# ATxmega128B1 device description
Architecture: AVR8_XMEGA; Family: AVR XMEGA
Registers are 8-bit, access not given, no defined reset value unless marked. A register's access mark holds for its fields unless they carry their own. Offsets are from the block's base; [hi:lo] are bit positions; lines under a group give offsets from that group; {n}, {i} and the like mark numbered series.

## ADC — Analog-to-Digital Converter
Instances: ADCA 0x0200, ADCB 0x0240
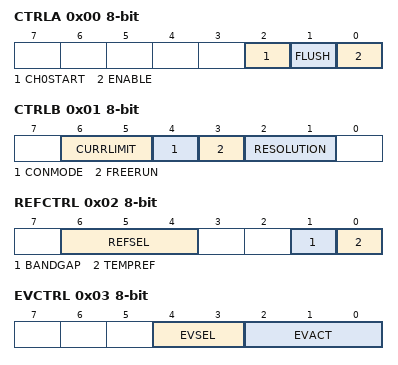
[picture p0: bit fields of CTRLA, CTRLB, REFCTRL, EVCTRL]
0x00 CTRLA — Control Register A
  [2] CH0START — Channel 0 Start Conversion
  [1] FLUSH — ADC Flush
  [0] ENABLE — Enable ADC
0x01 CTRLB — Control Register B
  [6:5] CURRLIMIT — Current limit
    0=NO (No current limit, 300ksps max sampling rate); 1=LOW (Low current limit, 250ksps max sampling rate); 2=MED (Medium current limit, 150ksps max sampling rate); 3=HIGH (High current limit, 50ksps max sampling rate)
  [4] CONMODE — Conversion Mode
  [3] FREERUN — Free Running Mode Enable
  [2:1] RESOLUTION — Result Resolution
    0=12BIT (12-bit right-adjusted result); 2=8BIT (8-bit right-adjusted result); 3=LEFT12BIT (12-bit left-adjusted result)
0x02 REFCTRL — Reference Control
  [6:4] REFSEL — Reference Selection
    0=INT1V (Internal 1V); 1=INTVCC (Internal VCC / 1.6); 2=AREFA (External reference on PORT A); 3=AREFB (External reference on PORT B); 4=INTVCC2 (Internal VCC / 2)
  [1] BANDGAP — Bandgap enable
  [0] TEMPREF — Temperature Reference Enable
0x03 EVCTRL — Event Control
  [4:3] EVSEL — Event Input Select
    {v}=Event Channel {v} (v=0..3)
  [2:0] EVACT — Event Action Select
    0=NONE (No event action); 1=CH0 (First event triggers channel 0); 6=SYNCSWEEP (The ADC is flushed and restarted for accurate timing)
0x04 PRESCALER — Clock Prescaler
  [2:0] PRESCALER — Clock Prescaler Selection
    0=DIV4 (Divide clock by 4); 1=DIV8 (Divide clock by 8); 2=DIV16 (Divide clock by 16); 3=DIV32 (Divide clock by 32); 4=DIV64 (Divide clock by 64); 5=DIV128 (Divide clock by 128); 6=DIV256 (Divide clock by 256); 7=DIV512 (Divide clock by 512)
0x06 INTFLAGS — Interrupt Flags
  [0] CH0IF — Channel 0 Interrupt Flag
0x07 TEMP — Temporary Register
0x08 SAMPCTRL — ADC Sampling Time Control Register
  [5:0] SAMPVAL — Sampling time control register
0x0C CAL 16-bit — Calibration Value
0x10 CH0RES 16-bit — Channel 0 Result
0x18 CMP 16-bit — Compare Value
0x20 CH0 group — ADC Channel 0
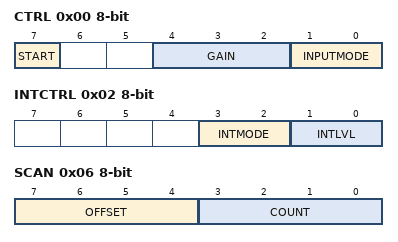
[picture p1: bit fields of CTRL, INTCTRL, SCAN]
  0x00 CTRL — Control Register
    [7] START — Channel Start Conversion
    [4:2] GAIN — Gain Factor
      0=1x gain; 1=2X (2x gain); 2=4X (4x gain); 3=8X (8x gain); 4=16X (16x gain); 5=32X (32x gain); 6=64X (64x gain); 7=DIV2 (x/2 gain)
    [1:0] INPUTMODE — Input Mode Select
      0=INTERNAL (Internal inputs, no gain (INPUTMODE = 0)); 1=SINGLEENDED (Single-ended input, no gain (INPUTMODE = 1)); 2=DIFF (Differential input, no gain (INPUTMODE = 2)); 3=DIFFWGAIN (Differential input, with gain (INPUTMODE = 3))
  0x01 MUXCTRL — MUX Control
    [6:3] MUXPOS — MUX selection on Positive ADC input
      {v}=PIN{v} (Input pin {v}) (v=0..15)
    [6:3] MUXINT — MUX selection on Internal ADC input
      0=TEMP (Temperature Reference); 1=BANDGAP (Bandgap Reference); 2=SCALEDVCC (1/10 scaled VCC)
    [2:0] MUXNEG — MUX selection on Negative ADC input
      0=PIN0 (Input pin 0 (if INPUTMODE = 2)); 1=PIN1 (Input pin 1 (if INPUTMODE = 2)); 2=PIN2 (Input pin 2 (if INPUTMODE = 2)); 3=PIN3 (Input pin 3 (if INPUTMODE = 2)); 0=PIN4 (Input pin 4 (if INPUTMODE = 3)); 1=PIN5 (Input pin 5 (if INPUTMODE = 3)); 2=PIN6 (Input pin 6 (if INPUTMODE = 3)); 3=PIN7 (Input pin 7 (if INPUTMODE = 3)); 5=GND_MODE3 (PAD Ground (if INPUTMODE = 2)); 7=INTGND_MODE3 (Internal Ground (if INPUTMODE = 2)); 4=INTGND_MODE4 (Internal Ground (if INPUTMODE = 3)); 7=GND_MODE4 (PAD Ground (if INPUTMODE = 3))
    [2:0] MUXNEGL — MUX selection on Negative ADC Input Gain on 4 LSB pins
      {v}=PIN{v} (Input pin {v}) (v=0..3); 5=GND (PAD ground); 7=INTGND (Internal ground)
    [2:0] MUXNEGH — MUX selection on Negative ADC Input Gain on 4 MSB pins
      {v}=PIN{v+4} (Input pin {v+4}) (v=0..3); 4=INTGND (Internal ground); 7=GND (PAD ground)
  0x02 INTCTRL — Channel Interrupt Control Register
    [3:2] INTMODE — Interrupt Mode
      0=COMPLETE (Interrupt on conversion complete); 1=BELOW (Interrupt on result below compare value); 3=ABOVE (Interrupt on result above compare value)
    [1:0] INTLVL — Interrupt Level
      0=OFF (Interrupt disabled); 1=LO (Low level); 2=MED (Medium level); 3=HI (High level)
  0x03 INTFLAGS — Interrupt Flags
    [0] CHIF — Channel Interrupt Flag
  0x04 RES 16-bit — Channel Result
  0x06 SCAN — Input Channel Scan
    [7:4] OFFSET — Positive MUX setting offset
    [3:0] COUNT — Number of Channels included in scan
